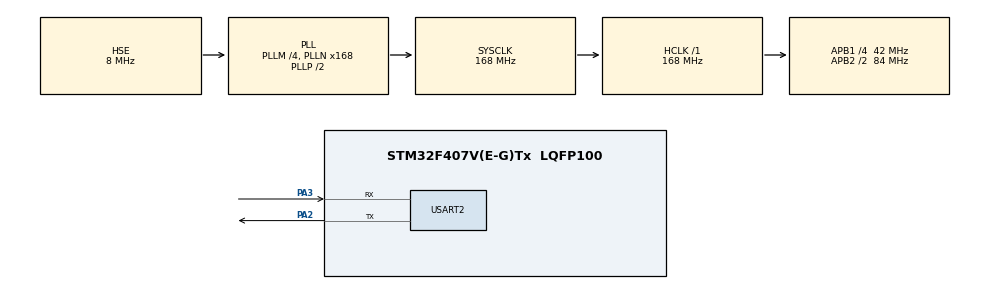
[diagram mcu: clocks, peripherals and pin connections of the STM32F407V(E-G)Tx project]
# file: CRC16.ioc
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Mcu.Family=STM32F4
Mcu.Name=STM32F407V(E-G)Tx
Mcu.Package=LQFP100
NVIC.PriorityGroup=NVIC_PRIORITYGROUP_4
NVIC.TIM1_UP_TIM10_IRQn=true\:0\:0\:false\:false\:true\:true\:true\:true
PA2.Mode=Asynchronous
PA2.Signal=USART2_TX
PA3.Mode=Asynchronous
PA3.Signal=USART2_RX
PH0-OSC_IN.Mode=HSE-External-Oscillator
PH0-OSC_IN.Signal=RCC_OSC_IN
PH1-OSC_OUT.Mode=HSE-External-Oscillator
PH1-OSC_OUT.Signal=RCC_OSC_OUT
ProjectManager.HeapSize=0x200
ProjectManager.StackSize=0x400
ProjectManager.TargetToolchain=STM32CubeIDE
RCC.48MHZClocksFreq_Value=84000000
RCC.AHBFreq_Value=168000000
RCC.APB1CLKDivider=RCC_HCLK_DIV4
RCC.APB1Freq_Value=42000000
RCC.APB1TimFreq_Value=84000000
RCC.APB2CLKDivider=RCC_HCLK_DIV2
RCC.APB2Freq_Value=84000000
RCC.APB2TimFreq_Value=168000000
RCC.CortexFreq_Value=168000000
RCC.HCLKFreq_Value=168000000
RCC.HSE_VALUE=8000000
RCC.HSI_VALUE=16000000
RCC.LSE_VALUE=32768
RCC.PLLM=4
RCC.PLLN=168
RCC.PLLSourceVirtual=RCC_PLLSOURCE_HSE
RCC.SYSCLKFreq_VALUE=168000000
RCC.SYSCLKSource=RCC_SYSCLKSOURCE_PLLCLK
RCC.VCOOutputFreq_Value=336000000
USART2.VirtualMode=VM_ASYNC
VP_TIM10_VS_ClockSourceINT.Mode=Enable_Timer
board=custom

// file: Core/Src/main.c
/* USER CODE BEGIN Header */
/**
  ******************************************************************************
  * @file           : main.c
  * @brief          : Main program body
  ******************************************************************************
  * @attention
  *
  * Copyright (c) 2024 STMicroelectronics.
  * All rights reserved.
  *
  * This software is licensed under terms that can be found in the LICENSE file
  * in the root directory of this software component.
  * If no LICENSE file comes with this software, it is provided AS-IS.
  *
  ******************************************************************************
  */
/* USER CODE END Header */
#include "main.h"

/* USER CODE BEGIN Includes */
#include "string.h"
#include"stdio.h"
/* USER CODE END Includes */

/* USER CODE BEGIN PTD */
typedef struct {
    uint8_t hdr_sync;
    uint8_t hdr_ver;
    uint8_t hdr_len;
    uint8_t hdr_devId;
    uint8_t data[16];
    uint16_t crc16;
} TelemetryPacket;
/* USER CODE END PTD */

TIM_HandleTypeDef htim10;

UART_HandleTypeDef huart2;

void SystemClock_Config(void);
static void MX_GPIO_Init(void);
static void MX_TIM10_Init(void);
static void MX_USART2_UART_Init(void);

/* USER CODE BEGIN 0 */
uint16_t calcCRC16(uint8_t *pt, uint8_t msglen)
{
	uint16_t crc16_data = 0;
	uint8_t data=0;
	for(uint8_t mlen=0; mlen<msglen; mlen++){
		data = pt[mlen]^((uint8_t)(crc16_data)&(uint8_t)(0xFF));
		data ^= data << 4;
		crc16_data = ((((uint16_t)data << 8) | ((crc16_data & 0xFF00) >> 8))
				          ^ (uint8_t)(data >> 4)
				          ^ ((uint16_t)data << 3));
	}
	return(crc16_data);
}
void sendTelemetryPacket(UART_HandleTypeDef *huart) {
    TelemetryPacket packet;
    packet.hdr_sync = 0x55;
    packet.hdr_ver = 0x00;
    packet.hdr_len = sizeof(packet);
    packet.hdr_devId = 0x02;

    memset(packet.data, 0, sizeof(packet.data));
     packet.data[0] = 164;
     packet.data[1] = 92;
     packet.data[2] = 0;
     packet.data[3] = 43;
     packet.data[4] = 25;
     packet.data[5] = 0;
     packet.data[6] = 243;
     packet.data[7] = 0;
     packet.data[8] = 7;
     packet.data[9] = 0;
     packet.data[10] = 28;
     packet.data[11] = 43;
     packet.data[12] = 73;
     packet.data[13] = 135;
     packet.data[14] = 14;
     packet.data[15] = 0;

    //CRC16
    packet.crc16 = calcCRC16((uint8_t *)&packet, sizeof(packet) - 2);

    // Send the packet
    HAL_UART_Transmit(huart, (uint8_t *)&packet, sizeof(packet), HAL_MAX_DELAY);
}

void HAL_TIM_PeriodElapsedCallback(TIM_HandleTypeDef *htim) {
    if (htim->Instance == TIM10) {
        // Code to execute every 10Hz
        sendTelemetryPacket(&huart2);
    }
}

/* USER CODE END 0 */

int main(void)
{

  /* MCU Configuration--------------------------------------------------------*/

  /* Reset of all peripherals, Initializes the Flash interface and the Systick. */
  HAL_Init();

  /* Configure the system clock */
  SystemClock_Config();

  /* Initialize all configured peripherals */
  MX_GPIO_Init();
  MX_TIM10_Init();
  MX_USART2_UART_Init();
  /* USER CODE BEGIN 2 */
  HAL_TIM_Base_Start_IT(&htim10);
  /* USER CODE END 2 */

  /* Infinite loop */
  /* USER CODE BEGIN WHILE */
  while (1)
  {
//	  sendTelemetryPacket(&huart2);
//	         HAL_Delay(1000);
   /* USER CODE END WHILE */

  }
}

void SystemClock_Config(void)
{
  RCC_OscInitTypeDef RCC_OscInitStruct = {0};
  RCC_ClkInitTypeDef RCC_ClkInitStruct = {0};

  /** Configure the main internal regulator output voltage
  */
  __HAL_RCC_PWR_CLK_ENABLE();
  __HAL_PWR_VOLTAGESCALING_CONFIG(PWR_REGULATOR_VOLTAGE_SCALE1);

  /** Initializes the RCC Oscillators according to the specified parameters
  * in the RCC_OscInitTypeDef structure.
  */
  RCC_OscInitStruct.OscillatorType = RCC_OSCILLATORTYPE_HSE;
  RCC_OscInitStruct.HSEState = RCC_HSE_ON;
  RCC_OscInitStruct.PLL.PLLState = RCC_PLL_ON;
  RCC_OscInitStruct.PLL.PLLSource = RCC_PLLSOURCE_HSE;
  RCC_OscInitStruct.PLL.PLLM = 4;
  RCC_OscInitStruct.PLL.PLLN = 168;
  RCC_OscInitStruct.PLL.PLLP = RCC_PLLP_DIV2;
  RCC_OscInitStruct.PLL.PLLQ = 4;
  if (HAL_RCC_OscConfig(&RCC_OscInitStruct) != HAL_OK)
  {
    Error_Handler();
  }

  /** Initializes the CPU, AHB and APB buses clocks
  */
  RCC_ClkInitStruct.ClockType = RCC_CLOCKTYPE_HCLK|RCC_CLOCKTYPE_SYSCLK
                              |RCC_CLOCKTYPE_PCLK1|RCC_CLOCKTYPE_PCLK2;
  RCC_ClkInitStruct.SYSCLKSource = RCC_SYSCLKSOURCE_PLLCLK;
  RCC_ClkInitStruct.AHBCLKDivider = RCC_SYSCLK_DIV1;
  RCC_ClkInitStruct.APB1CLKDivider = RCC_HCLK_DIV4;
  RCC_ClkInitStruct.APB2CLKDivider = RCC_HCLK_DIV2;

  if (HAL_RCC_ClockConfig(&RCC_ClkInitStruct, FLASH_LATENCY_5) != HAL_OK)
  {
    Error_Handler();
  }
}

static void MX_TIM10_Init(void)
{

  htim10.Instance = TIM10;
  htim10.Init.Prescaler = 16800-1;
  htim10.Init.CounterMode = TIM_COUNTERMODE_UP;
  htim10.Init.Period = 10000-1;
  htim10.Init.ClockDivision = TIM_CLOCKDIVISION_DIV1;
  htim10.Init.AutoReloadPreload = TIM_AUTORELOAD_PRELOAD_DISABLE;
  if (HAL_TIM_Base_Init(&htim10) != HAL_OK)
  {
    Error_Handler();
  }

}

static void MX_USART2_UART_Init(void)
{

  huart2.Instance = USART2;
  huart2.Init.BaudRate = 115200;
  huart2.Init.WordLength = UART_WORDLENGTH_8B;
  huart2.Init.StopBits = UART_STOPBITS_1;
  huart2.Init.Parity = UART_PARITY_NONE;
  huart2.Init.Mode = UART_MODE_TX_RX;
  huart2.Init.HwFlowCtl = UART_HWCONTROL_NONE;
  huart2.Init.OverSampling = UART_OVERSAMPLING_16;
  if (HAL_UART_Init(&huart2) != HAL_OK)
  {
    Error_Handler();
  }

}

static void MX_GPIO_Init(void)
{

  /* GPIO Ports Clock Enable */
  __HAL_RCC_GPIOH_CLK_ENABLE();
  __HAL_RCC_GPIOA_CLK_ENABLE();

}

void Error_Handler(void)
{
  __disable_irq();
  while (1)
  {
  }
}
